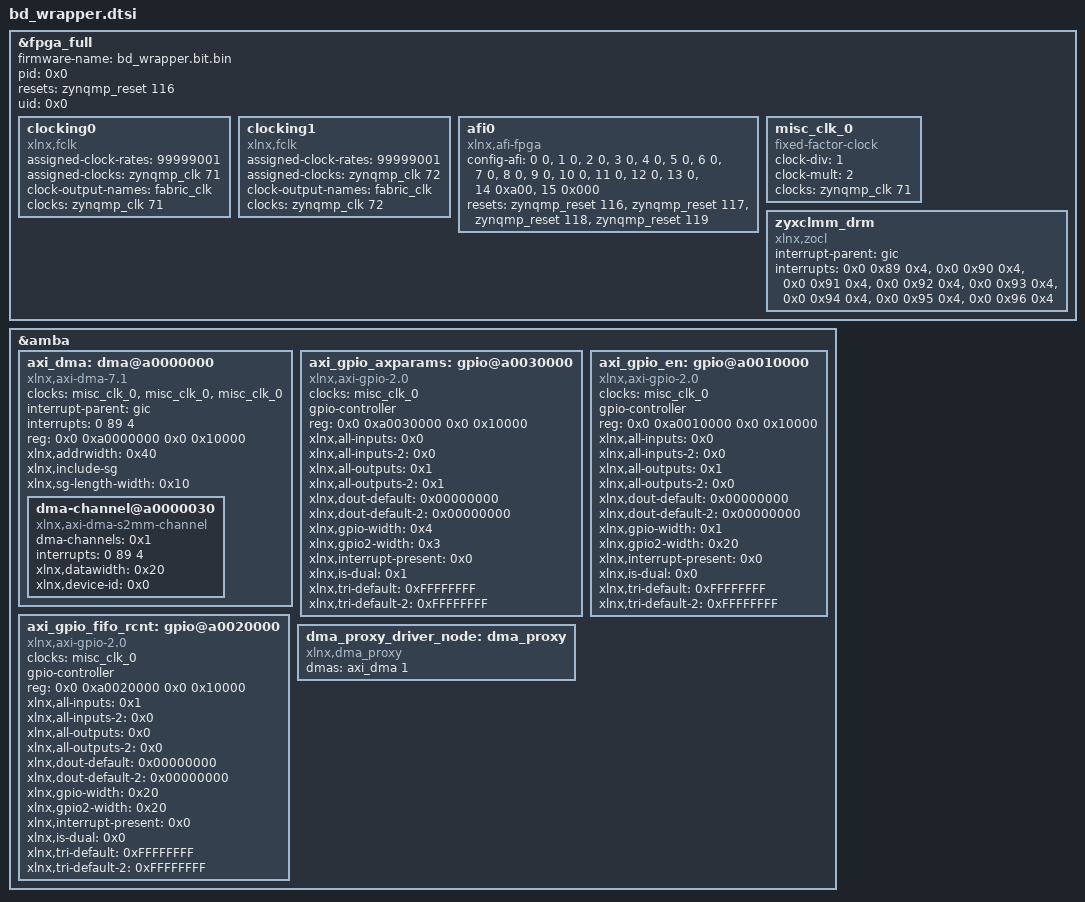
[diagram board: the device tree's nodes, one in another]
/*
 * CAUTION: This file is automatically generated by Xilinx.
 * Version: XSCT 2024.2
 * Today is: Fri Dec 20 15:56:02 2024
 */


/dts-v1/;
/plugin/;
&fpga_full {
	firmware-name = "bd_wrapper.bit.bin";
	pid = <0x0>;
	resets = <&zynqmp_reset 116>;
	uid = <0x0>;
	clocking0: clocking0 {
		#clock-cells = <0>;
		assigned-clock-rates = <99999001>;
		assigned-clocks = <&zynqmp_clk 71>;
		clock-output-names = "fabric_clk";
		clocks = <&zynqmp_clk 71>;
		compatible = "xlnx,fclk";
	};
	clocking1: clocking1 {
		#clock-cells = <0>;
		assigned-clock-rates = <99999001>;
		assigned-clocks = <&zynqmp_clk 72>;
		clock-output-names = "fabric_clk";
		clocks = <&zynqmp_clk 72>;
		compatible = "xlnx,fclk";
	};
	afi0: afi0 {
		compatible = "xlnx,afi-fpga";
		config-afi = < 0 0>, <1 0>, <2 0>, <3 0>, <4 0>, <5 0>, <6 0>, <7 0>, <8 0>, <9 0>, <10 0>, <11 0>, <12 0>, <13 0>, <14 0xa00>, <15 0x000>;
		resets = <&zynqmp_reset 116>, <&zynqmp_reset 117>, <&zynqmp_reset 118>, <&zynqmp_reset 119>;
	};
	misc_clk_0: misc_clk_0 {
		#clock-cells = <0>;
		clock-div = <1>;
		clock-mult = <2>;
		clocks = <&zynqmp_clk 71>;
		compatible = "fixed-factor-clock";
	};
	zyxclmm_drm {
		compatible = "xlnx,zocl";
		interrupt-parent = <&gic>;
		interrupts = <0x0 0x89 0x4>, <0x0 0x90 0x4>, <0x0 0x91 0x4>, <0x0 0x92 0x4>, <0x0 0x93 0x4>, <0x0 0x94 0x4>, <0x0 0x95 0x4>, <0x0 0x96 0x4>;
	};
};
&amba {
	#address-cells = <2>;
	#size-cells = <2>;
	axi_dma: dma@a0000000 {
		#dma-cells = <1>;
		clock-names = "m_axi_s2mm_aclk", "m_axi_sg_aclk", "s_axi_lite_aclk";
		clocks = <&misc_clk_0>, <&misc_clk_0>, <&misc_clk_0>;
		compatible = "xlnx,axi-dma-7.1", "xlnx,axi-dma-1.00.a";
		interrupt-names = "s2mm_introut";
		interrupt-parent = <&gic>;
		interrupts = <0 89 4>;
		reg = <0x0 0xa0000000 0x0 0x10000>;
		xlnx,addrwidth = <0x40>;
		xlnx,include-sg ;
		xlnx,sg-length-width = <0x10>;
		dma-channel@a0000030 {
			compatible = "xlnx,axi-dma-s2mm-channel";
			dma-channels = <0x1>;
			interrupts = <0 89 4>;
			xlnx,datawidth = <0x20>;
			xlnx,device-id = <0x0>;
		};
	};
	axi_gpio_axparams: gpio@a0030000 {
		#gpio-cells = <2>;
		clock-names = "s_axi_aclk";
		clocks = <&misc_clk_0>;
		compatible = "xlnx,axi-gpio-2.0", "xlnx,xps-gpio-1.00.a";
		gpio-controller ;
		reg = <0x0 0xa0030000 0x0 0x10000>;
		xlnx,all-inputs = <0x0>;
		xlnx,all-inputs-2 = <0x0>;
		xlnx,all-outputs = <0x1>;
		xlnx,all-outputs-2 = <0x1>;
		xlnx,dout-default = <0x00000000>;
		xlnx,dout-default-2 = <0x00000000>;
		xlnx,gpio-width = <0x4>;
		xlnx,gpio2-width = <0x3>;
		xlnx,interrupt-present = <0x0>;
		xlnx,is-dual = <0x1>;
		xlnx,tri-default = <0xFFFFFFFF>;
		xlnx,tri-default-2 = <0xFFFFFFFF>;
	};
	axi_gpio_en: gpio@a0010000 {
		#gpio-cells = <2>;
		clock-names = "s_axi_aclk";
		clocks = <&misc_clk_0>;
		compatible = "xlnx,axi-gpio-2.0", "xlnx,xps-gpio-1.00.a";
		gpio-controller ;
		reg = <0x0 0xa0010000 0x0 0x10000>;
		xlnx,all-inputs = <0x0>;
		xlnx,all-inputs-2 = <0x0>;
		xlnx,all-outputs = <0x1>;
		xlnx,all-outputs-2 = <0x0>;
		xlnx,dout-default = <0x00000000>;
		xlnx,dout-default-2 = <0x00000000>;
		xlnx,gpio-width = <0x1>;
		xlnx,gpio2-width = <0x20>;
		xlnx,interrupt-present = <0x0>;
		xlnx,is-dual = <0x0>;
		xlnx,tri-default = <0xFFFFFFFF>;
		xlnx,tri-default-2 = <0xFFFFFFFF>;
	};
	axi_gpio_fifo_rcnt: gpio@a0020000 {
		#gpio-cells = <2>;
		clock-names = "s_axi_aclk";
		clocks = <&misc_clk_0>;
		compatible = "xlnx,axi-gpio-2.0", "xlnx,xps-gpio-1.00.a";
		gpio-controller ;
		reg = <0x0 0xa0020000 0x0 0x10000>;
		xlnx,all-inputs = <0x1>;
		xlnx,all-inputs-2 = <0x0>;
		xlnx,all-outputs = <0x0>;
		xlnx,all-outputs-2 = <0x0>;
		xlnx,dout-default = <0x00000000>;
		xlnx,dout-default-2 = <0x00000000>;
		xlnx,gpio-width = <0x20>;
		xlnx,gpio2-width = <0x20>;
		xlnx,interrupt-present = <0x0>;
		xlnx,is-dual = <0x0>;
		xlnx,tri-default = <0xFFFFFFFF>;
		xlnx,tri-default-2 = <0xFFFFFFFF>;
	};
	dma_proxy_driver_node: dma_proxy {
		compatible ="xlnx,dma_proxy";
		dmas = <&axi_dma 1>;
		dma-names = "dma_proxy_spk_to_ps";
		//dma-coherent;
	};
};
